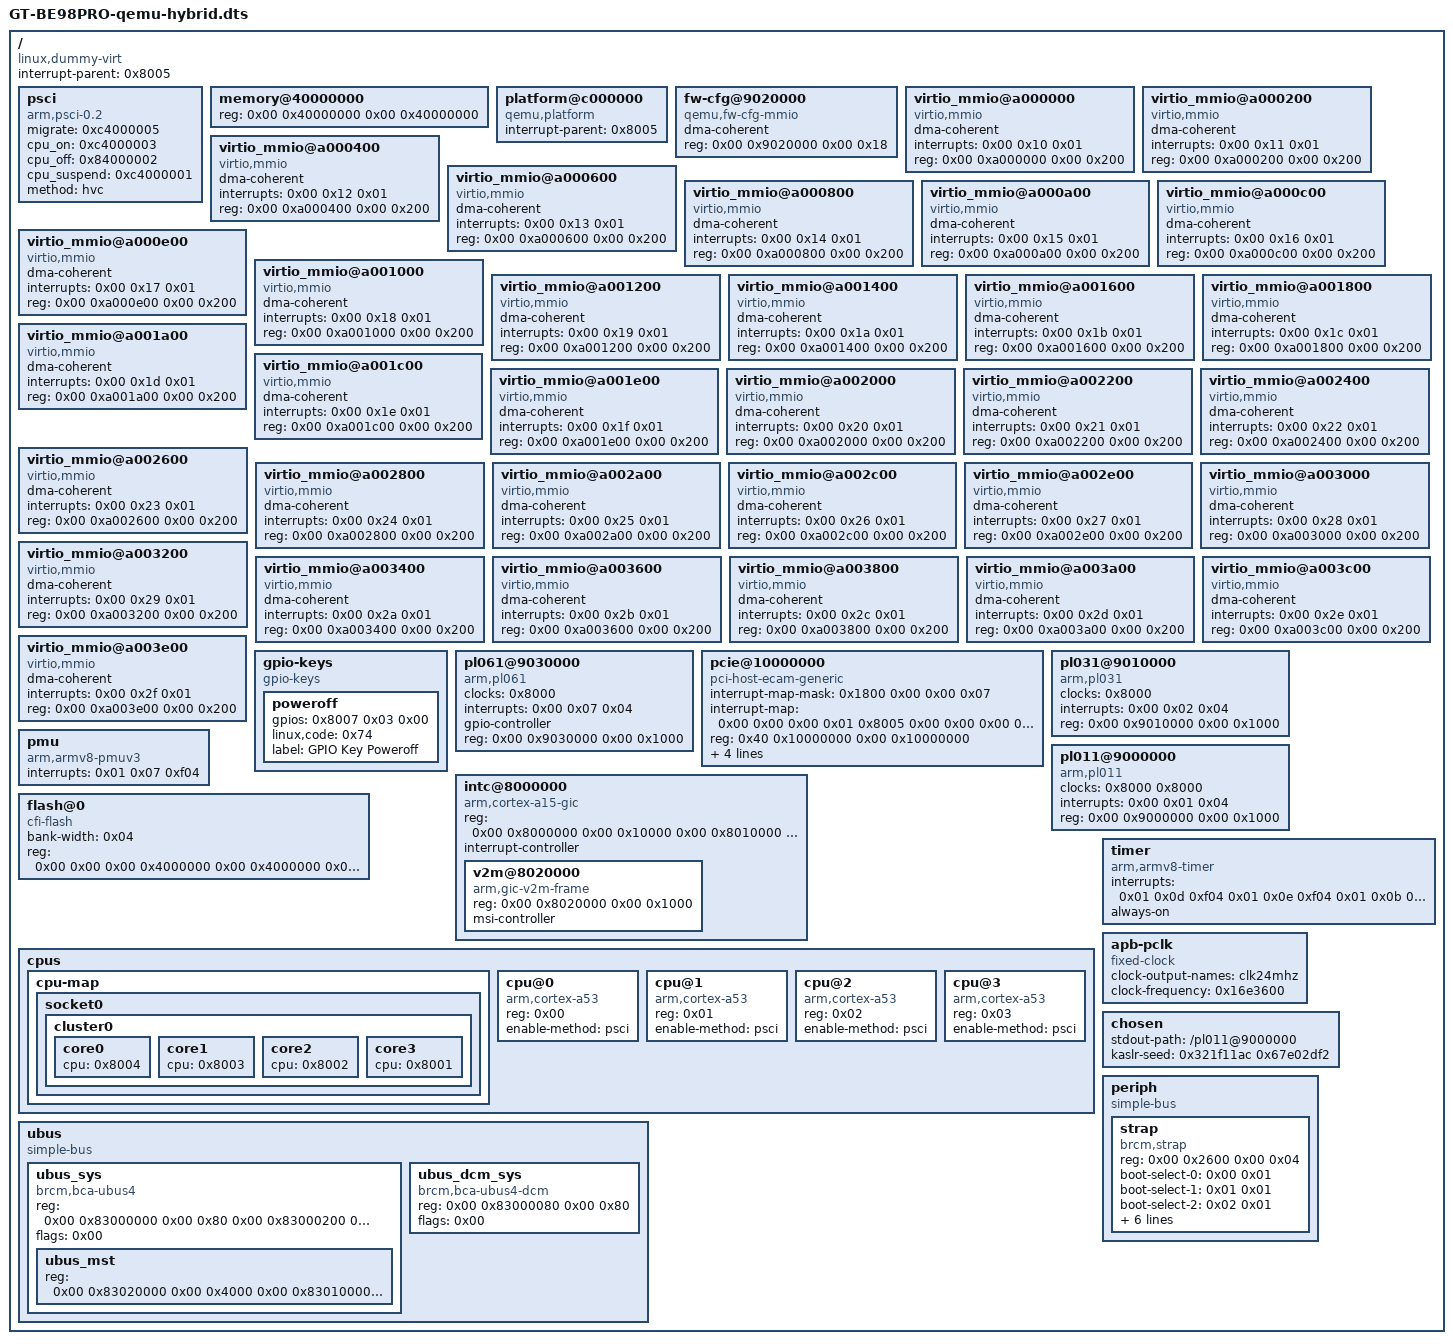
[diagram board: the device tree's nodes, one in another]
/dts-v1/;

/ {
	interrupt-parent = <0x8005>;
	#size-cells = <0x02>;
	#address-cells = <0x02>;
	compatible = "linux,dummy-virt";

	psci {
		migrate = <0xc4000005>;
		cpu_on = <0xc4000003>;
		cpu_off = <0x84000002>;
		cpu_suspend = <0xc4000001>;
		method = "hvc";
		compatible = "arm,psci-0.2\0arm,psci";
	};

	memory@40000000 {
		reg = <0x00 0x40000000 0x00 0x40000000>;
		device_type = "memory";
	};

	platform@c000000 {
		interrupt-parent = <0x8005>;
		ranges = <0x00 0x00 0xc000000 0x2000000>;
		#address-cells = <0x01>;
		#size-cells = <0x01>;
		compatible = "qemu,platform\0simple-bus";
	};

	fw-cfg@9020000 {
		dma-coherent;
		reg = <0x00 0x9020000 0x00 0x18>;
		compatible = "qemu,fw-cfg-mmio";
	};

	virtio_mmio@a000000 {
		dma-coherent;
		interrupts = <0x00 0x10 0x01>;
		reg = <0x00 0xa000000 0x00 0x200>;
		compatible = "virtio,mmio";
	};

	virtio_mmio@a000200 {
		dma-coherent;
		interrupts = <0x00 0x11 0x01>;
		reg = <0x00 0xa000200 0x00 0x200>;
		compatible = "virtio,mmio";
	};

	virtio_mmio@a000400 {
		dma-coherent;
		interrupts = <0x00 0x12 0x01>;
		reg = <0x00 0xa000400 0x00 0x200>;
		compatible = "virtio,mmio";
	};

	virtio_mmio@a000600 {
		dma-coherent;
		interrupts = <0x00 0x13 0x01>;
		reg = <0x00 0xa000600 0x00 0x200>;
		compatible = "virtio,mmio";
	};

	virtio_mmio@a000800 {
		dma-coherent;
		interrupts = <0x00 0x14 0x01>;
		reg = <0x00 0xa000800 0x00 0x200>;
		compatible = "virtio,mmio";
	};

	virtio_mmio@a000a00 {
		dma-coherent;
		interrupts = <0x00 0x15 0x01>;
		reg = <0x00 0xa000a00 0x00 0x200>;
		compatible = "virtio,mmio";
	};

	virtio_mmio@a000c00 {
		dma-coherent;
		interrupts = <0x00 0x16 0x01>;
		reg = <0x00 0xa000c00 0x00 0x200>;
		compatible = "virtio,mmio";
	};

	virtio_mmio@a000e00 {
		dma-coherent;
		interrupts = <0x00 0x17 0x01>;
		reg = <0x00 0xa000e00 0x00 0x200>;
		compatible = "virtio,mmio";
	};

	virtio_mmio@a001000 {
		dma-coherent;
		interrupts = <0x00 0x18 0x01>;
		reg = <0x00 0xa001000 0x00 0x200>;
		compatible = "virtio,mmio";
	};

	virtio_mmio@a001200 {
		dma-coherent;
		interrupts = <0x00 0x19 0x01>;
		reg = <0x00 0xa001200 0x00 0x200>;
		compatible = "virtio,mmio";
	};

	virtio_mmio@a001400 {
		dma-coherent;
		interrupts = <0x00 0x1a 0x01>;
		reg = <0x00 0xa001400 0x00 0x200>;
		compatible = "virtio,mmio";
	};

	virtio_mmio@a001600 {
		dma-coherent;
		interrupts = <0x00 0x1b 0x01>;
		reg = <0x00 0xa001600 0x00 0x200>;
		compatible = "virtio,mmio";
	};

	virtio_mmio@a001800 {
		dma-coherent;
		interrupts = <0x00 0x1c 0x01>;
		reg = <0x00 0xa001800 0x00 0x200>;
		compatible = "virtio,mmio";
	};

	virtio_mmio@a001a00 {
		dma-coherent;
		interrupts = <0x00 0x1d 0x01>;
		reg = <0x00 0xa001a00 0x00 0x200>;
		compatible = "virtio,mmio";
	};

	virtio_mmio@a001c00 {
		dma-coherent;
		interrupts = <0x00 0x1e 0x01>;
		reg = <0x00 0xa001c00 0x00 0x200>;
		compatible = "virtio,mmio";
	};

	virtio_mmio@a001e00 {
		dma-coherent;
		interrupts = <0x00 0x1f 0x01>;
		reg = <0x00 0xa001e00 0x00 0x200>;
		compatible = "virtio,mmio";
	};

	virtio_mmio@a002000 {
		dma-coherent;
		interrupts = <0x00 0x20 0x01>;
		reg = <0x00 0xa002000 0x00 0x200>;
		compatible = "virtio,mmio";
	};

	virtio_mmio@a002200 {
		dma-coherent;
		interrupts = <0x00 0x21 0x01>;
		reg = <0x00 0xa002200 0x00 0x200>;
		compatible = "virtio,mmio";
	};

	virtio_mmio@a002400 {
		dma-coherent;
		interrupts = <0x00 0x22 0x01>;
		reg = <0x00 0xa002400 0x00 0x200>;
		compatible = "virtio,mmio";
	};

	virtio_mmio@a002600 {
		dma-coherent;
		interrupts = <0x00 0x23 0x01>;
		reg = <0x00 0xa002600 0x00 0x200>;
		compatible = "virtio,mmio";
	};

	virtio_mmio@a002800 {
		dma-coherent;
		interrupts = <0x00 0x24 0x01>;
		reg = <0x00 0xa002800 0x00 0x200>;
		compatible = "virtio,mmio";
	};

	virtio_mmio@a002a00 {
		dma-coherent;
		interrupts = <0x00 0x25 0x01>;
		reg = <0x00 0xa002a00 0x00 0x200>;
		compatible = "virtio,mmio";
	};

	virtio_mmio@a002c00 {
		dma-coherent;
		interrupts = <0x00 0x26 0x01>;
		reg = <0x00 0xa002c00 0x00 0x200>;
		compatible = "virtio,mmio";
	};

	virtio_mmio@a002e00 {
		dma-coherent;
		interrupts = <0x00 0x27 0x01>;
		reg = <0x00 0xa002e00 0x00 0x200>;
		compatible = "virtio,mmio";
	};

	virtio_mmio@a003000 {
		dma-coherent;
		interrupts = <0x00 0x28 0x01>;
		reg = <0x00 0xa003000 0x00 0x200>;
		compatible = "virtio,mmio";
	};

	virtio_mmio@a003200 {
		dma-coherent;
		interrupts = <0x00 0x29 0x01>;
		reg = <0x00 0xa003200 0x00 0x200>;
		compatible = "virtio,mmio";
	};

	virtio_mmio@a003400 {
		dma-coherent;
		interrupts = <0x00 0x2a 0x01>;
		reg = <0x00 0xa003400 0x00 0x200>;
		compatible = "virtio,mmio";
	};

	virtio_mmio@a003600 {
		dma-coherent;
		interrupts = <0x00 0x2b 0x01>;
		reg = <0x00 0xa003600 0x00 0x200>;
		compatible = "virtio,mmio";
	};

	virtio_mmio@a003800 {
		dma-coherent;
		interrupts = <0x00 0x2c 0x01>;
		reg = <0x00 0xa003800 0x00 0x200>;
		compatible = "virtio,mmio";
	};

	virtio_mmio@a003a00 {
		dma-coherent;
		interrupts = <0x00 0x2d 0x01>;
		reg = <0x00 0xa003a00 0x00 0x200>;
		compatible = "virtio,mmio";
	};

	virtio_mmio@a003c00 {
		dma-coherent;
		interrupts = <0x00 0x2e 0x01>;
		reg = <0x00 0xa003c00 0x00 0x200>;
		compatible = "virtio,mmio";
	};

	virtio_mmio@a003e00 {
		dma-coherent;
		interrupts = <0x00 0x2f 0x01>;
		reg = <0x00 0xa003e00 0x00 0x200>;
		compatible = "virtio,mmio";
	};

	gpio-keys {
		#address-cells = <0x01>;
		#size-cells = <0x00>;
		compatible = "gpio-keys";

		poweroff {
			gpios = <0x8007 0x03 0x00>;
			linux,code = <0x74>;
			label = "GPIO Key Poweroff";
		};
	};

	pl061@9030000 {
		phandle = <0x8007>;
		clock-names = "apb_pclk";
		clocks = <0x8000>;
		interrupts = <0x00 0x07 0x04>;
		gpio-controller;
		#gpio-cells = <0x02>;
		compatible = "arm,pl061\0arm,primecell";
		reg = <0x00 0x9030000 0x00 0x1000>;
	};

	pcie@10000000 {
		interrupt-map-mask = <0x1800 0x00 0x00 0x07>;
		interrupt-map = <0x00 0x00 0x00 0x01 0x8005 0x00 0x00 0x00 0x03 0x04 0x00 0x00 0x00 0x02 0x8005 0x00 0x00 0x00 0x04 0x04 0x00 0x00 0x00 0x03 0x8005 0x00 0x00 0x00 0x05 0x04 0x00 0x00 0x00 0x04 0x8005 0x00 0x00 0x00 0x06 0x04 0x800 0x00 0x00 0x01 0x8005 0x00 0x00 0x00 0x04 0x04 0x800 0x00 0x00 0x02 0x8005 0x00 0x00 0x00 0x05 0x04 0x800 0x00 0x00 0x03 0x8005 0x00 0x00 0x00 0x06 0x04 0x800 0x00 0x00 0x04 0x8005 0x00 0x00 0x00 0x03 0x04 0x1000 0x00 0x00 0x01 0x8005 0x00 0x00 0x00 0x05 0x04 0x1000 0x00 0x00 0x02 0x8005 0x00 0x00 0x00 0x06 0x04 0x1000 0x00 0x00 0x03 0x8005 0x00 0x00 0x00 0x03 0x04 0x1000 0x00 0x00 0x04 0x8005 0x00 0x00 0x00 0x04 0x04 0x1800 0x00 0x00 0x01 0x8005 0x00 0x00 0x00 0x06 0x04 0x1800 0x00 0x00 0x02 0x8005 0x00 0x00 0x00 0x03 0x04 0x1800 0x00 0x00 0x03 0x8005 0x00 0x00 0x00 0x04 0x04 0x1800 0x00 0x00 0x04 0x8005 0x00 0x00 0x00 0x05 0x04>;
		#interrupt-cells = <0x01>;
		ranges = <0x1000000 0x00 0x00 0x00 0x3eff0000 0x00 0x10000 0x2000000 0x00 0x10000000 0x00 0x10000000 0x00 0x2eff0000 0x3000000 0x80 0x00 0x80 0x00 0x80 0x00>;
		reg = <0x40 0x10000000 0x00 0x10000000>;
		msi-parent = <0x8006>;
		dma-coherent;
		bus-range = <0x00 0xff>;
		linux,pci-domain = <0x00>;
		#size-cells = <0x02>;
		#address-cells = <0x03>;
		device_type = "pci";
		compatible = "pci-host-ecam-generic";
	};

	pl031@9010000 {
		clock-names = "apb_pclk";
		clocks = <0x8000>;
		interrupts = <0x00 0x02 0x04>;
		reg = <0x00 0x9010000 0x00 0x1000>;
		compatible = "arm,pl031\0arm,primecell";
	};

	pl011@9000000 {
		clock-names = "uartclk\0apb_pclk";
		clocks = <0x8000 0x8000>;
		interrupts = <0x00 0x01 0x04>;
		reg = <0x00 0x9000000 0x00 0x1000>;
		compatible = "arm,pl011\0arm,primecell";
	};

	pmu {
		interrupts = <0x01 0x07 0xf04>;
		compatible = "arm,armv8-pmuv3";
	};

	intc@8000000 {
		phandle = <0x8005>;
		reg = <0x00 0x8000000 0x00 0x10000 0x00 0x8010000 0x00 0x10000>;
		compatible = "arm,cortex-a15-gic";
		ranges;
		#size-cells = <0x02>;
		#address-cells = <0x02>;
		interrupt-controller;
		#interrupt-cells = <0x03>;

		v2m@8020000 {
			phandle = <0x8006>;
			reg = <0x00 0x8020000 0x00 0x1000>;
			msi-controller;
			compatible = "arm,gic-v2m-frame";
		};
	};

	flash@0 {
		bank-width = <0x04>;
		reg = <0x00 0x00 0x00 0x4000000 0x00 0x4000000 0x00 0x4000000>;
		compatible = "cfi-flash";
	};

	cpus {
		#size-cells = <0x00>;
		#address-cells = <0x01>;

		cpu-map {

			socket0 {

				cluster0 {

					core0 {
						cpu = <0x8004>;
					};

					core1 {
						cpu = <0x8003>;
					};

					core2 {
						cpu = <0x8002>;
					};

					core3 {
						cpu = <0x8001>;
					};
				};
			};
		};

		cpu@0 {
			phandle = <0x8004>;
			reg = <0x00>;
			enable-method = "psci";
			compatible = "arm,cortex-a53";
			device_type = "cpu";
		};

		cpu@1 {
			phandle = <0x8003>;
			reg = <0x01>;
			enable-method = "psci";
			compatible = "arm,cortex-a53";
			device_type = "cpu";
		};

		cpu@2 {
			phandle = <0x8002>;
			reg = <0x02>;
			enable-method = "psci";
			compatible = "arm,cortex-a53";
			device_type = "cpu";
		};

		cpu@3 {
			phandle = <0x8001>;
			reg = <0x03>;
			enable-method = "psci";
			compatible = "arm,cortex-a53";
			device_type = "cpu";
		};
	};

	timer {
		interrupts = <0x01 0x0d 0xf04 0x01 0x0e 0xf04 0x01 0x0b 0xf04 0x01 0x0a 0xf04>;
		always-on;
		compatible = "arm,armv8-timer\0arm,armv7-timer";
	};

	apb-pclk {
		phandle = <0x8000>;
		clock-output-names = "clk24mhz";
		clock-frequency = <0x16e3600>;
		#clock-cells = <0x00>;
		compatible = "fixed-clock";
	};

	chosen {
		stdout-path = "/pl011@9000000";
		kaslr-seed = <0x321f11ac 0x67e02df2>;
	};

	/* Minimal stock BCM6813 discovery nodes for hybrid checkpointing. */
	periph {
		compatible = "simple-bus";
		#address-cells = <0x02>;
		#size-cells = <0x02>;
		ranges = <0x00 0x00 0x00 0xff800000 0x00 0x62000>;

		strap {
			compatible = "brcm,strap";
			reg = <0x00 0x2600 0x00 0x04>;
			boot-select-0 = <0x00 0x01>;
			boot-select-1 = <0x01 0x01>;
			boot-select-2 = <0x02 0x01>;
			boot-select-3 = <0x03 0x01>;
			boot-select-4 = <0x04 0x01>;
			boot-select-5 = <0x05 0x01>;
			bootrom-boot = <0x0c 0x01>;
			strap-cpu-slow-freq = <0x10 0x01>;
			strap-vco-clock = <0x0d 0x02>;
		};
	};

	ubus {
		compatible = "simple-bus";
		#address-cells = <0x02>;
		#size-cells = <0x02>;
		ranges;

		ubus_sys {
			compatible = "brcm,bca-ubus4";
			#address-cells = <0x02>;
			#size-cells = <0x02>;
			ranges;
			reg = <0x00 0x83000000 0x00 0x80
			       0x00 0x83000200 0x00 0x80
			       0x00 0x810a0400 0x00 0x400>;
			reg-names = "ubus_systop", "ubus_registration",
				    "ubus_coherency_port";
			flags = <0x00>;

			ubus_mst {
				reg-names = "BIU", "PER", "USB", "SPU", "PCIE0",
					    "PCIE1", "PCIE2", "PCIE3", "DMA0",
					    "DMA1", "DMA2", "RQ0", "RQ1", "QM", "MPM";
				reg = <0x00 0x83020000 0x00 0x4000
				       0x00 0x83010000 0x00 0x4000
				       0x00 0x83018000 0x00 0x4000
				       0x00 0x83028000 0x00 0x4000
				       0x00 0x83030000 0x00 0x4000
				       0x00 0x83038000 0x00 0x4000
				       0x00 0x83040000 0x00 0x4000
				       0x00 0x83048000 0x00 0x4000
				       0x00 0x83058000 0x00 0x4000
				       0x00 0x83060000 0x00 0x4000
				       0x00 0x83070000 0x00 0x4000
				       0x00 0x83078000 0x00 0x4000
				       0x00 0x83080000 0x00 0x4000
				       0x00 0x83050000 0x00 0x4000
				       0x00 0x83088000 0x00 0x4000>;
			};
		};

		ubus_dcm_sys {
			compatible = "brcm,bca-ubus4-dcm";
			reg = <0x00 0x83000080 0x00 0x80>;
			reg-names = "ubus_dcm_clk";
			flags = <0x00>;
		};
	};
};
